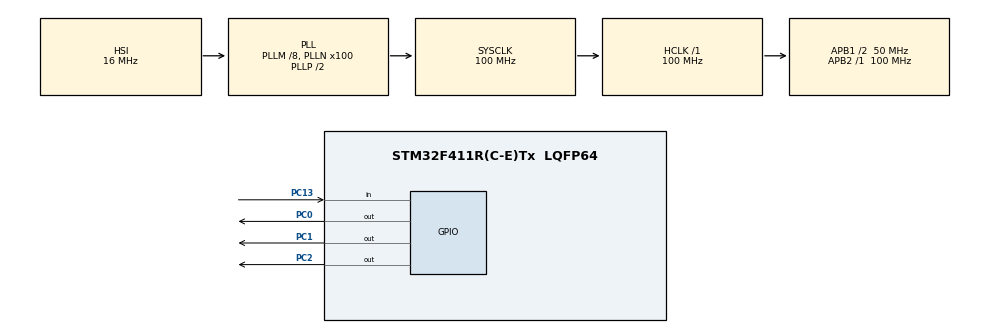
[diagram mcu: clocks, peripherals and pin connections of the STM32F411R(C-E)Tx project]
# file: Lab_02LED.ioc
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Mcu.Family=STM32F4
Mcu.Name=STM32F411R(C-E)Tx
Mcu.Package=LQFP64
NVIC.PriorityGroup=NVIC_PRIORITYGROUP_4
PC0.Signal=GPIO_Output
PC1.Signal=GPIO_Output
PC13-ANTI_TAMP.Signal=GPIO_Input
PC2.Signal=GPIO_Output
ProjectManager.HeapSize=0x200
ProjectManager.StackSize=0x400
ProjectManager.TargetToolchain=MDK-ARM V5
RCC.48MHZClocksFreq_Value=50000000
RCC.AHBFreq_Value=100000000
RCC.APB1CLKDivider=RCC_HCLK_DIV2
RCC.APB1Freq_Value=50000000
RCC.APB1TimFreq_Value=100000000
RCC.APB2Freq_Value=100000000
RCC.APB2TimFreq_Value=100000000
RCC.CortexFreq_Value=100000000
RCC.HCLKFreq_Value=100000000
RCC.HSE_VALUE=25000000
RCC.HSI_VALUE=16000000
RCC.LSE_VALUE=32768
RCC.PLLM=8
RCC.PLLN=100
RCC.SYSCLKFreq_VALUE=100000000
RCC.SYSCLKSource=RCC_SYSCLKSOURCE_PLLCLK
RCC.VCOOutputFreq_Value=200000000
board=custom

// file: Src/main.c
/* USER CODE BEGIN Header */
/**
  ******************************************************************************
  * @file           : main.c
  * @brief          : Main program body
  ******************************************************************************
  ** This notice applies to any and all portions of this file
  * that are not between comment pairs USER CODE BEGIN and
  * USER CODE END. Other portions of this file, whether
  * inserted by the user or by software development tools
  * are owned by their respective copyright owners.
  *
  * COPYRIGHT(c) 2019 STMicroelectronics
  *
  * Redistribution and use in source and binary forms, with or without modification,
  * are permitted provided that the following conditions are met:
  *   1. Redistributions of source code must retain the above copyright notice,
  *      this list of conditions and the following disclaimer.
  *   2. Redistributions in binary form must reproduce the above copyright notice,
  *      this list of conditions and the following disclaimer in the documentation
  *      and/or other materials provided with the distribution.
  *   3. Neither the name of STMicroelectronics nor the names of its contributors
  *      may be used to endorse or promote products derived from this software
  *      without specific prior written permission.
  *
  * THIS SOFTWARE IS PROVIDED BY THE COPYRIGHT HOLDERS AND CONTRIBUTORS "AS IS"
  * AND ANY EXPRESS OR IMPLIED WARRANTIES, INCLUDING, BUT NOT LIMITED TO, THE
  * IMPLIED WARRANTIES OF MERCHANTABILITY AND FITNESS FOR A PARTICULAR PURPOSE ARE
  * DISCLAIMED. IN NO EVENT SHALL THE COPYRIGHT HOLDER OR CONTRIBUTORS BE LIABLE
  * FOR ANY DIRECT, INDIRECT, INCIDENTAL, SPECIAL, EXEMPLARY, OR CONSEQUENTIAL
  * DAMAGES (INCLUDING, BUT NOT LIMITED TO, PROCUREMENT OF SUBSTITUTE GOODS OR
  * SERVICES; LOSS OF USE, DATA, OR PROFITS; OR BUSINESS INTERRUPTION) HOWEVER
  * CAUSED AND ON ANY THEORY OF LIABILITY, WHETHER IN CONTRACT, STRICT LIABILITY,
  * OR TORT (INCLUDING NEGLIGENCE OR OTHERWISE) ARISING IN ANY WAY OUT OF THE USE
  * OF THIS SOFTWARE, EVEN IF ADVISED OF THE POSSIBILITY OF SUCH DAMAGE.
  *
  ******************************************************************************
  */
/* USER CODE END Header */

#include "main.h"
#include "gpio.h"

void SystemClock_Config(void);

int main(void)
{

  /* MCU Configuration--------------------------------------------------------*/

  /* Reset of all peripherals, Initializes the Flash interface and the Systick. */
  HAL_Init();

  /* Configure the system clock */
  SystemClock_Config();

  /* Initialize all configured peripherals */
  MX_GPIO_Init();

  /* Infinite loop */
  /* USER CODE BEGIN WHILE */
	uint8_t n;

  while (1)
  {
    /* USER CODE END WHILE */

    /* USER CODE BEGIN 3 */
		for(n=0; n<=2; n++)
		{

			GPIOC-> BSRR =0x00070000;
			HAL_Delay(500);

			GPIOC-> BSRR =0x00000004 >> n;
			HAL_Delay(500);

		}
  }
  /* USER CODE END 3 */
}

void SystemClock_Config(void)
{
  RCC_OscInitTypeDef RCC_OscInitStruct = {0};
  RCC_ClkInitTypeDef RCC_ClkInitStruct = {0};

  /**Configure the main internal regulator output voltage
  */
  __HAL_RCC_PWR_CLK_ENABLE();
  __HAL_PWR_VOLTAGESCALING_CONFIG(PWR_REGULATOR_VOLTAGE_SCALE1);
  /**Initializes the CPU, AHB and APB busses clocks
  */
  RCC_OscInitStruct.OscillatorType = RCC_OSCILLATORTYPE_HSI;
  RCC_OscInitStruct.HSIState = RCC_HSI_ON;
  RCC_OscInitStruct.HSICalibrationValue = RCC_HSICALIBRATION_DEFAULT;
  RCC_OscInitStruct.PLL.PLLState = RCC_PLL_ON;
  RCC_OscInitStruct.PLL.PLLSource = RCC_PLLSOURCE_HSI;
  RCC_OscInitStruct.PLL.PLLM = 8;
  RCC_OscInitStruct.PLL.PLLN = 100;
  RCC_OscInitStruct.PLL.PLLP = RCC_PLLP_DIV2;
  RCC_OscInitStruct.PLL.PLLQ = 4;
  if (HAL_RCC_OscConfig(&RCC_OscInitStruct) != HAL_OK)
  {
    Error_Handler();
  }
  /**Initializes the CPU, AHB and APB busses clocks
  */
  RCC_ClkInitStruct.ClockType = RCC_CLOCKTYPE_HCLK|RCC_CLOCKTYPE_SYSCLK
                              |RCC_CLOCKTYPE_PCLK1|RCC_CLOCKTYPE_PCLK2;
  RCC_ClkInitStruct.SYSCLKSource = RCC_SYSCLKSOURCE_PLLCLK;
  RCC_ClkInitStruct.AHBCLKDivider = RCC_SYSCLK_DIV1;
  RCC_ClkInitStruct.APB1CLKDivider = RCC_HCLK_DIV2;
  RCC_ClkInitStruct.APB2CLKDivider = RCC_HCLK_DIV1;

  if (HAL_RCC_ClockConfig(&RCC_ClkInitStruct, FLASH_LATENCY_3) != HAL_OK)
  {
    Error_Handler();
  }
}

void Error_Handler(void)
{
}

/************************ (C) COPYRIGHT STMicroelectronics *****END OF FILE****/
